# VPE_CSC register map
Vendor: Texas Instruments
Peripheral module from a debugger description file (folder am571x).
Registers are 32-bit, access per field, reset 0x0 unless marked. A register's access mark holds for its fields unless they carry their own. Offsets are as the file gives them; lines under a group give offsets from that group; [hi:lo] are bit positions; {n}, {i} and the like mark numbered series; 'fields as' and 'values as' point back to an identical list; <NAME> marks a mode.

## VPE_CSC
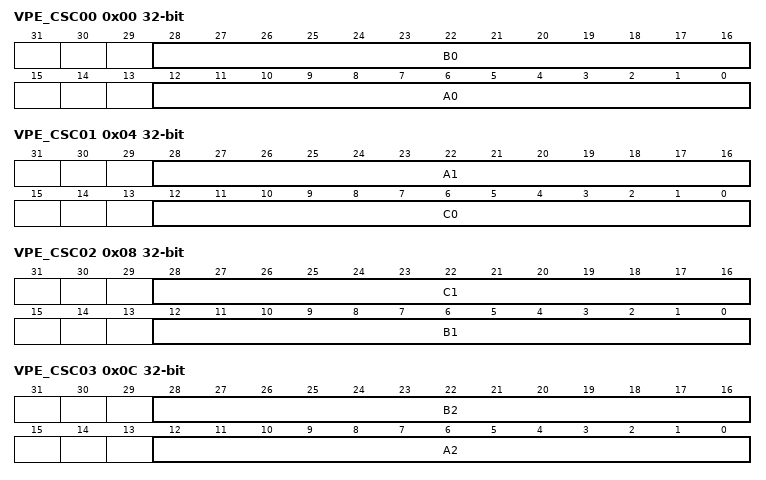
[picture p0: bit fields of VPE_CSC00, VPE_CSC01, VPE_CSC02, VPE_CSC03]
0x00 VPE_CSC00
  [28:16] B0 rw — Coefficients of color space converter. This coefficient is a real number in the range of -4. to +4 represent in Q3.10 format. The MSB is sign bit. (Same format conversion as A0 inVPE_CSC00)
  [12:0] A0 rw — Its is represented as Q3.10 number. So the value ranges from -4 to +4. To convert a decimal number, multiply the number by 1024 and write it in the register in hex format. For example, to program 0.673, 0x2B1 should be written in the register. (int)(0.673 X 1024) = (int)689.152 = 689 = 0x2B1. If the real number is negative, then multiply it by 1024, and convert it to 2's compliment format in 12-bit. For example, if a coefficient is - 1.893, 0x186E needs to be written in the register. (int)(-1.893*1024)= -1938 = 0x186E (2'S compliment format of -1938 in 13-bit width)
0x04 VPE_CSC01
  [28:16] A1 rw — Coefficients of color space converter. This coefficient is a real number in the range of -4. to +4 represent in Q3.10 format. The MSB is sign bit. (Same format conversion as A0 inVPE_CSC00)
  [12:0] C0 rw — Coefficients of color space converter. This coefficient is a real number in the range of -4. to +4 represent in Q3.10 format. The MSB is sign bit. (Same format conversion as A0 inVPE_CSC00)
0x08 VPE_CSC02
  [28:16] C1 rw — Coefficients of color space converter. This coefficient is a real number in the range of -4. to +4 represent in Q3.10 format. The MSB is sign bit. (Same format conversion as A0 inVPE_CSC00)
  [12:0] B1 rw — Coefficients of color space converter. This coefficient is a real number in the range of -4. to +4 represent in Q3.10 format. The MSB is sign bit. (Same format conversion as A0 inVPE_CSC00)
0x0C VPE_CSC03
  [28:16] B2 rw — Coefficients of color space converter. This coefficient is a real number in the range of -4. to +4 represent in Q3.10 format. The MSB is sign bit. (Same format conversion as A0 inVPE_CSC00)
  [12:0] A2 rw — Coefficients of color space converter. This coefficient is a real number in the range of -4. to +4 represent in Q3.10 format. The MSB is sign bit. (Same format conversion as A0 inVPE_CSC00)
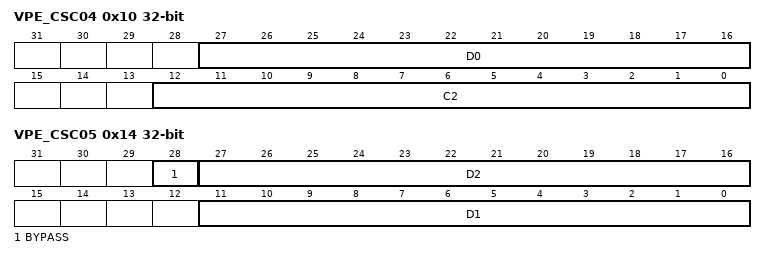
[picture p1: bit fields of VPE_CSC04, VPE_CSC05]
0x10 VPE_CSC04
  [27:16] D0 rw — Coefficients of color space converter. This coefficient is an integer number in the range of 2048. It is in 12-bit wide 2's compliment format. The MSB is sign bit. For example, if this coefficient is 749, then 0x2ED (hex format) should be assigned to this register. Another example, if this coefficient is -1021, then 0xC03 should be assigned to this register.
  [12:0] C2 rw — Coefficients of color space converter. This coefficient is a real number in the range of -4. to +4 represent in Q3.10 format. The MSB is sign bit. (Same format conversion as A0 inVPE_CSC00)
0x14 VPE_CSC05
  [28] BYPASS rw — Full CSC bypass mode
  [27:16] D2 rw — Coefficients of color space converter. This coefficient is an integer number in the range of -2048 to 2048. It is in 12-bit wide 2's compliment format. The MSB is sign bit. (Same format conversion as D0 inVPE_CSC04)
  [11:0] D1 rw — Coefficients of color space converter. This coefficient is an integer number in the range of -2048 to 2048. It is in 12-bit wide 2's compliment format. The MSB is sign bit. (Same format conversion as D0 inVPE_CSC04)
